# GCT301S register map
Vendor: SZGC; Series: GCT301S; File version: 1.2
ARM 32-bit Cortex-M0 Microcontroller based device, CPU clock up to 8MHz, etc.
CPU: CM0 r0p0, little endian, no MPU, no FPU, 2 interrupt priority bits
Registers are 32-bit, read-write, reset 0x0 unless marked. A register's access mark holds for its fields unless they carry their own. Offsets are from the block's base; lines under a group give offsets from that group; [hi:lo] are bit positions; {n}, {i} and the like mark numbered series; 'fields as' and 'values as' point back to an identical list; <NAME> marks a mode.

## Memory map
0x40000000 RTC size 0x1000
0x40001000 TIMER0 size 0x1000
0x40002000 TIMER1 size 0x1000
0x40003000 TIMER2 size 0x1000
0x40004000 TIMER3 size 0x1000
0x40005000 TIMER4 size 0x1000
0x40006000 WDT size 0x1000 — Watchdog
0x40008000 LCD size 0x1000 — LCD controller
0x4000A000 ADC size 0x1000
0x40010000 UART0 size 0x1000
0x40011000 UART1 size 0x1000
0x40012000 UART2 size 0x1000
0x40013000 UART3 size 0x1000
0x40014000 UART4 size 0x1000
0x40015000 UART5 size 0x1000
0x40017000 CFLASH size 0x1000 — Code Flash controller
0x40018000 DFLASH size 0x1000 — Data flash controller
0x4001A000 SPI size 0x1000
0x4001D000 SYSCTRL size 0x1000
0x40080000 GPIOA size 0x1000
0x40081000 GPIOB size 0x1000
0x40082000 GPIOC size 0x1000

## Interrupts
1 WDT
2 RTC
3 UART0
4 UART1
5 UART2
6 UART3
7 UART4
8 UART5
9 SPI
10 CFLASH
11 DFLASH
12 TIMER0
13 TIMER1
14 TIMER2
15 TIMER3
16 TIMER4
17 EXT0 (SYSCTRL) — GPIO 2 interrupt
18 EXT1 (SYSCTRL) — GPIO 3 interrupt
19 EXT2 (SYSCTRL) — GPIO 4 interrupt
20 EXT3 (SYSCTRL) — GPIO 5 interrupt
21 LCD
22 ADC
23 GPIOA
24 GPIOB
25 GPIOC
26 IRQ26 (SYSCTRL)
27 IRQ27 (SYSCTRL)
28 IRQ28 (SYSCTRL)
29 IRQ29 (SYSCTRL)
30 IRQ30 (SYSCTRL)
31 IRQ31 (SYSCTRL)

## SYSCTRL
Base 0x4001D000
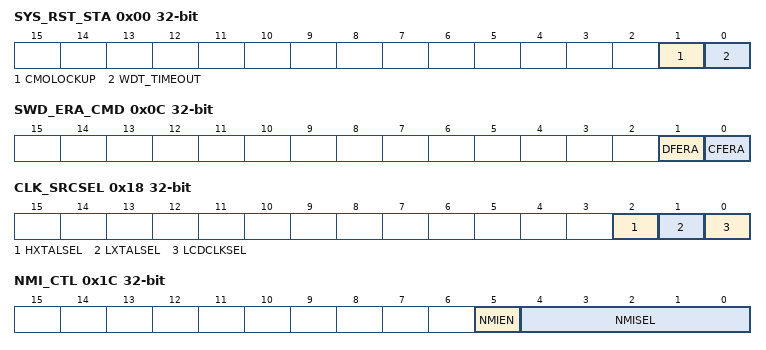
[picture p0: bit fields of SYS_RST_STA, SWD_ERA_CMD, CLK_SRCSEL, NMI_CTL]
0x00 SYS_RST_STA — System reset status
  [1] CMOLOCKUP — Core lockup
  [0] WDT_TIMEOUT — Watchdog timeout
0x04 SYS_CLK_STA — System clock status
  [0] DPLL_LOCK — DPLL lock status
0x08 SWD_ERA_KEY — SWD erase key (0xC3A1)
  [31:0] ERA_KEY
0x0C SWD_ERA_CMD — SWD erase command
  [1] DFERA, [0] CFERA
0x10 RST_CR — Reset configuration
  [7:0] RSTN_KEY
0x14 CLK_DIVSEL reset 0x1
  [2:0] DIVSEL — Clock divider selection
0x18 CLK_SRCSEL
  [2] HXTALSEL — HSRC/HXTAL selection
  [1] LXTALSEL — HSCLK/LXTAL selection
  [0] LCDCLKSEL — LCD clock selection
0x1C NMI_CTL — NMI control
  [5] NMIEN, [4:0] NMISEL
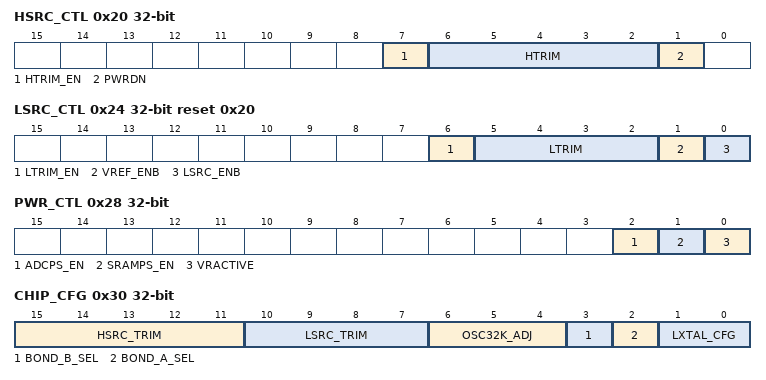
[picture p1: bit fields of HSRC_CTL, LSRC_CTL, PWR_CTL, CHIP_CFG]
0x20 HSRC_CTL — HSRC control
  [7] HTRIM_EN, [6:2] HTRIM, [1] PWRDN
0x24 LSRC_CTL reset 0x20 — LSRC control
  [6] LTRIM_EN, [5:2] LTRIM, [1] VREF_ENB, [0] LSRC_ENB
0x28 PWR_CTL — Power control
  [2] ADCPS_EN, [1] SRAMPS_EN, [0] VRACTIVE
0x2C DPLL_CTL — DPLL control
  [0] DPLL_EN
0x30 CHIP_CFG ro — Chip configuration
  [15:11] HSRC_TRIM, [10:7] LSRC_TRIM, [6:4] OSC32K_ADJ, [3] BOND_B_SEL, [2] BOND_A_SEL, [1:0] LXTAL_CFG
0x34 SYS_CPL ro — System code protection
  [1:0] CPL
0x38 HXTAL_CTL — HXTAL control
  [0] HXTAL_EN
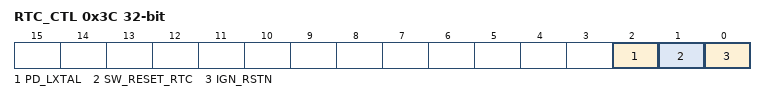
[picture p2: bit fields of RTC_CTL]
0x3C RTC_CTL — RTC control
  [2] PD_LXTAL, [1] SW_RESET_RTC, [0] IGN_RSTN
0x40 WDT_CTL — Watchdog trigger control
  [0] WDT_TRIG

## WDT — Watchdog
Base 0x40006000
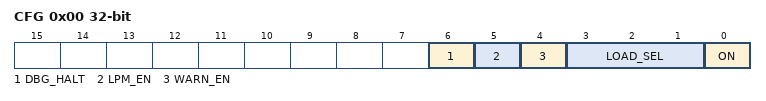
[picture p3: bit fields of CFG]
0x00 CFG — Watchdog configuration
  [6] DBG_HALT ro, [5] LPM_EN ro, [4] WARN_EN ro, [3:1] LOAD_SEL ro, [0] ON ro
0x04 IF — Interrupt flag
  [0] WARN_IF
0x08 FEED wo reset 0xBB66AA55 — Watchdog feed command, write 0xBB66AA55 to feed.
0x0C LOAD ro — Watchdog timeout reload selection.
0x10 COUNT — Watchdog latched count value.
0x14 LATCH — Update COUNT register.
  [0] LATCH_EN

## Licence text in the file
ARM Limited (ARM) is supplying this software for use with Cortex-M processor based microcontroller, but can be equally used for other suitable processor architectures. This file can be freely distributed. Modifications to this file shall be clearly marked. . THIS SOFTWARE IS PROVIDED "AS IS". NO WARRANTIES, WHETHER EXPRESS, IMPLIED. OR STATUTORY, INCLUDING, BUT NOT LIMITED TO, IMPLIED WARRANTIES OF. MERCHANTABILITY AND FITNESS FOR A PARTICULAR PURPOSE APPLY TO THIS SOFTWARE. ARM SHALL NOT, IN ANY CIRCUMSTANCES, BE LIABLE FOR SPECIAL, INCIDENTAL, OR. CONSEQUENTIAL DAMAGES, FOR ANY REASON WHATSOEVER.

## Notices in the file
Copyright (C) 2012-2014 ARM Limited. All rights reserved.
Purpose: System Viewer Description (SVD) Example (Schema Version 1.1)
This is a description of a none-existent and incomplete device
for demonstration purposes only.
Redistribution and use in source and binary forms, with or without
modification, are permitted provided that the following conditions are met:
- Redistributions of source code must retain the above copyright
notice, this list of conditions and the following disclaimer.
- Redistributions in binary form must reproduce the above copyright
notice, this list of conditions and the following disclaimer in the
documentation and/or other materials provided with the distribution.
- Neither the name of ARM nor the names of its contributors may be used
to endorse or promote products derived from this software without
specific prior written permission.
THIS SOFTWARE IS PROVIDED BY THE COPYRIGHT HOLDERS AND CONTRIBUTORS "AS IS"
AND ANY EXPRESS OR IMPLIED WARRANTIES, INCLUDING, BUT NOT LIMITED TO, THE
ARE DISCLAIMED. IN NO EVENT SHALL COPYRIGHT HOLDERS AND CONTRIBUTORS BE
LIABLE FOR ANY DIRECT, INDIRECT, INCIDENTAL, SPECIAL, EXEMPLARY, OR
CONSEQUENTIAL DAMAGES (INCLUDING, BUT NOT LIMITED TO, PROCUREMENT OF
SUBSTITUTE GOODS OR SERVICES; LOSS OF USE, DATA, OR PROFITS; OR BUSINESS
INTERRUPTION) HOWEVER CAUSED AND ON ANY THEORY OF LIABILITY, WHETHER IN
CONTRACT, STRICT LIABILITY, OR TORT (INCLUDING NEGLIGENCE OR OTHERWISE)
ARISING IN ANY WAY OUT OF THE USE OF THIS SOFTWARE, EVEN IF ADVISED OF THE
POSSIBILITY OF SUCH DAMAGE.
